# HTNB32L-XXX register map
File version: 0.9
CPU: CM3 r0p0, little endian, no MPU, no FPU, 3 interrupt priority bits
Registers are 32-bit, read-write, reset 0x0 unless marked. A register's access mark holds for its fields unless they carry their own. Offsets are from the block's base; [hi:lo] are bit positions; {n}, {i} and the like mark numbered series; 'fields as' and 'values as' point back to an identical list.

## IOCON (part 3 of 3) — IOCON pin configuration
Base 0x4002C000
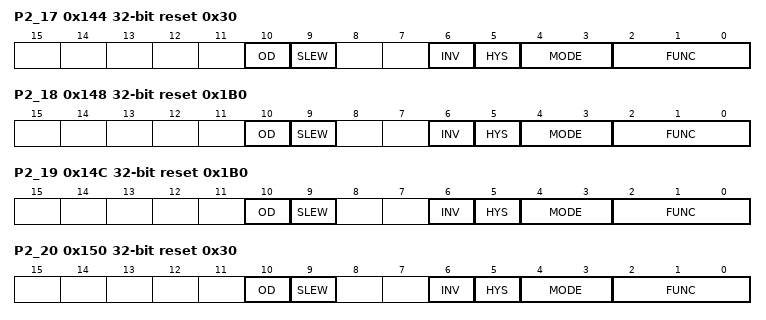
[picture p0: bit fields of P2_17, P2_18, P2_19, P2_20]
0x144 P2_17 reset 0x30 — I/O configuration register for pin P2[17]
  [10] OD — Open-drain mode.
    0=DISABLE; 1=ENABLED (Open-drain mode enabled. This is not a true open-drain mode. Input cannot be pulled up above VDD.)
  [9] SLEW — Driver slew rate
    0=STANDARD (Standard mode, output slew rate control is enabled. More outputs can be switched simultaneously.); 1=FAST (Fast mode, slew rate control is disabled. Refer to the appropriate specific device data sheet for details.)
  [6] INV — Invert input
    0=INPUT_NOT_INVERTED (Input not inverted (HIGH on pin reads as 1, LOW on pin reads as 0).); 1=INPUT_INVERTED_HIGH (Input inverted (HIGH on pin reads as 0, LOW on pin reads as 1).)
  [5] HYS — Hysteresis.
    0=DISABLE; 1=ENABLE
  [4:3] MODE — Selects function mode (on-chip pull-up/pull-down resistor control).
    0=INACTIVE (Inactive (no pull-down/pull-up resistor enabled).); 1=PULLDOWN_EN (Pull-down resistor enabled.); 2=PULLUP_EN (Pull-up resistor enabled.); 3=REPEATER_MODE
  [2:0] FUNC — Selects pin function for pin P2[17]
    0=P2_17 (General purpose digital input/output pin.); 1=EMC_RAS (LOW active SDRAM Row Address Strobe.)
0x148 P2_18 reset 0x1B0 — I/O configuration register for pin P2[18]
  [10] OD — Open-drain mode.
    values as P2_17.OD
  [9] SLEW — Driver slew rate
    values as P2_17.SLEW
  [6] INV — Invert input
    values as P2_17.INV
  [5] HYS — Hysteresis.
    0=DISABLE; 1=ENABLE
  [4:3] MODE — Selects function mode (on-chip pull-up/pull-down resistor control).
    values as P2_17.MODE
  [2:0] FUNC — Selects pin function for pin P2[18]
    0=P2_18 (General purpose digital input/output pin.); 1=EMC_CLK_0 (SDRAM clock 0.)
0x14C P2_19 reset 0x1B0 — I/O configuration register for pin P2[19]
  [10] OD — Open-drain mode.
    values as P2_17.OD
  [9] SLEW — Driver slew rate
    values as P2_17.SLEW
  [6] INV — Invert input
    values as P2_17.INV
  [5] HYS — Hysteresis.
    0=DISABLE; 1=ENABLE
  [4:3] MODE — Selects function mode (on-chip pull-up/pull-down resistor control).
    values as P2_17.MODE
  [2:0] FUNC — Selects pin function for pin P2[19]
    0=P2_19 (General purpose digital input/output pin.); 1=EMC_CLK_1 (SDRAM clock 1.)
0x150 P2_20 reset 0x30 — I/O configuration register for pin P2[20]
  [10] OD — Open-drain mode.
    values as P2_17.OD
  [9] SLEW — Driver slew rate
    values as P2_17.SLEW
  [6] INV — Invert input
    values as P2_17.INV
  [5] HYS — Hysteresis.
    0=DISABLE; 1=ENABLE
  [4:3] MODE — Selects function mode (on-chip pull-up/pull-down resistor control).
    values as P2_17.MODE
  [2:0] FUNC — Selects pin function for pin P2[20]
    0=P2_20 (General purpose digital input/output pin.); 1=EMC_DYCS0 (SDRAM chip select 0.)
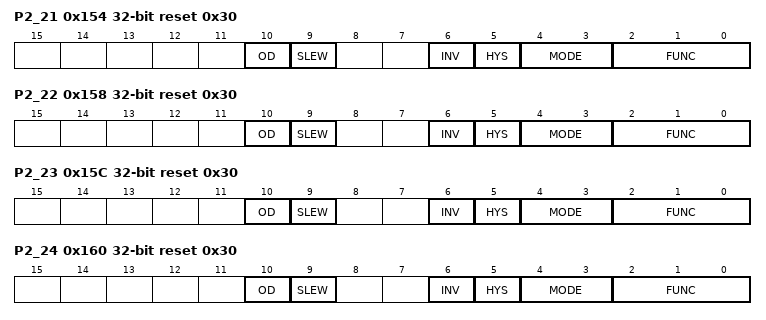
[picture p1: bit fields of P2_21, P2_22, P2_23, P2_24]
0x154 P2_21 reset 0x30 — I/O configuration register for pin P2[21]
  [10] OD — Open-drain mode.
    values as P2_17.OD
  [9] SLEW — Driver slew rate
    values as P2_17.SLEW
  [6] INV — Invert input
    values as P2_17.INV
  [5] HYS — Hysteresis.
    0=DISABLE; 1=ENABLE
  [4:3] MODE — Selects function mode (on-chip pull-up/pull-down resistor control).
    values as P2_17.MODE
  [2:0] FUNC — Selects pin function for pin P2[21]
    0=P2_21 (General purpose digital input/output pin.); 1=EMC_DYCS1 (SDRAM chip select 1.)
0x158 P2_22 reset 0x30 — I/O configuration register for pin P2[22]
  [10] OD — Open-drain mode.
    values as P2_17.OD
  [9] SLEW — Driver slew rate
    values as P2_17.SLEW
  [6] INV — Invert input
    values as P2_17.INV
  [5] HYS — Hysteresis.
    0=DISABLE; 1=ENABLE
  [4:3] MODE — Selects function mode (on-chip pull-up/pull-down resistor control).
    values as P2_17.MODE
  [2:0] FUNC — Selects pin function for pin P2[22]
    0=P2_22 (General purpose digital input/output pin.); 1=EMC_DYCS2 (SDRAM chip select 2.); 2=SSP0_SCK (Serial clock for SSP0.); 3=T3_CAP0 (Capture input for Timer 3, channel 0.)
0x15C P2_23 reset 0x30 — I/O configuration register for pin P2[23]
  [10] OD — Open-drain mode.
    values as P2_17.OD
  [9] SLEW — Driver slew rate
    values as P2_17.SLEW
  [6] INV — Invert input
    values as P2_17.INV
  [5] HYS — Hysteresis.
    0=DISABLE; 1=ENABLE
  [4:3] MODE — Selects function mode (on-chip pull-up/pull-down resistor control).
    values as P2_17.MODE
  [2:0] FUNC — Selects pin function for pin P2[23]
    0=P2_23 (General purpose digital input/output pin.); 1=EMC_DYCS3 (SDRAM chip select 3.); 2=SSP0_SSEL (Slave Select for SSP0.); 3=T3_CAP1 (Capture input for Timer 3, channel 1.)
0x160 P2_24 reset 0x30 — I/O configuration register for pin P2[24]
  [10] OD — Open-drain mode.
    values as P2_17.OD
  [9] SLEW — Driver slew rate
    values as P2_17.SLEW
  [6] INV — Invert input
    values as P2_17.INV
  [5] HYS — Hysteresis.
    0=DISABLE; 1=ENABLE
  [4:3] MODE — Selects function mode (on-chip pull-up/pull-down resistor control).
    values as P2_17.MODE
  [2:0] FUNC — Selects pin function for pin P2[24]
    0=P2_24 (General purpose digital input/output pin.); 1=EMC_CKE0 (SDRAM clock enable 0.)
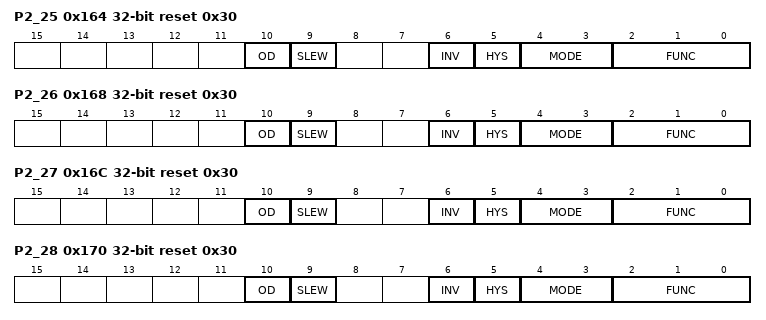
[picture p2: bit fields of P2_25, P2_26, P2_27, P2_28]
0x164 P2_25 reset 0x30 — I/O configuration register for pin P2[25]
  [10] OD — Open-drain mode.
    values as P2_17.OD
  [9] SLEW — Driver slew rate
    values as P2_17.SLEW
  [6] INV — Invert input
    values as P2_17.INV
  [5] HYS — Hysteresis.
    0=DISABLE; 1=ENABLE
  [4:3] MODE — Selects function mode (on-chip pull-up/pull-down resistor control).
    values as P2_17.MODE
  [2:0] FUNC — Selects pin function for pin P2[25]
    0=P2_25 (General purpose digital input/output pin.); 1=EMC_CKE1 (SDRAM clock enable 1.)
0x168 P2_26 reset 0x30 — I/O configuration register for pin P2[26]
  [10] OD — Open-drain mode.
    values as P2_17.OD
  [9] SLEW — Driver slew rate
    values as P2_17.SLEW
  [6] INV — Invert input
    values as P2_17.INV
  [5] HYS — Hysteresis.
    0=DISABLE; 1=ENABLE
  [4:3] MODE — Selects function mode (on-chip pull-up/pull-down resistor control).
    values as P2_17.MODE
  [2:0] FUNC — Selects pin function for pin P2[26]
    0=P2_26 (General purpose digital input/output pin.); 1=EMC_CKE2 (SDRAM clock enable 2.); 2=SSP0_MISO (Master In Slave Out for SSP0.); 3=T3_MAT0 (Match output for Timer 3, channel 0.)
0x16C P2_27 reset 0x30 — I/O configuration register for pin P2[27]
  [10] OD — Open-drain mode.
    values as P2_17.OD
  [9] SLEW — Driver slew rate
    values as P2_17.SLEW
  [6] INV — Invert input
    values as P2_17.INV
  [5] HYS — Hysteresis.
    0=DISABLE; 1=ENABLE
  [4:3] MODE — Selects function mode (on-chip pull-up/pull-down resistor control).
    values as P2_17.MODE
  [2:0] FUNC — Selects pin function for pin P2[27]
    0=P2_27 (General purpose digital input/output pin.); 1=EMC_CKE3 (SDRAM clock enable 3.); 2=SSP0_MOSI (Master Out Slave In for SSP0.); 3=T3_MAT1 (Match output for Timer 3, channel 1.)
0x170 P2_28 reset 0x30 — I/O configuration register for pin P2[28]
  [10] OD — Open-drain mode.
    values as P2_17.OD
  [9] SLEW — Driver slew rate
    values as P2_17.SLEW
  [6] INV — Invert input
    values as P2_17.INV
  [5] HYS — Hysteresis.
    0=DISABLE; 1=ENABLE
  [4:3] MODE — Selects function mode (on-chip pull-up/pull-down resistor control).
    values as P2_17.MODE
  [2:0] FUNC — Selects pin function for pin P2[28]
    0=P2_28 (General purpose digital input/output pin.); 1=EMC_DQM0 (Data mask 0 used with SDRAM and static devices.)
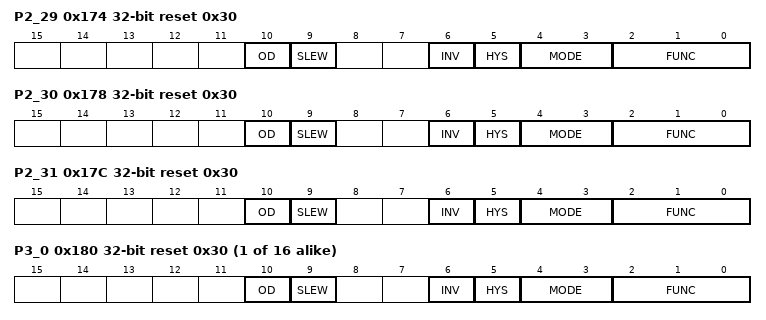
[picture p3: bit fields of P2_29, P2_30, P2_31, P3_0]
0x174 P2_29 reset 0x30 — I/O configuration register for pin P2[29]
  [10] OD — Open-drain mode.
    values as P2_17.OD
  [9] SLEW — Driver slew rate
    values as P2_17.SLEW
  [6] INV — Invert input
    values as P2_17.INV
  [5] HYS — Hysteresis.
    0=DISABLE; 1=ENABLE
  [4:3] MODE — Selects function mode (on-chip pull-up/pull-down resistor control).
    values as P2_17.MODE
  [2:0] FUNC — Selects pin function for pin P2[29]
    0=P2_29 (General purpose digital input/output pin.); 1=EMC_DQM1 (Data mask 1 used with SDRAM and static devices.)
0x178 P2_30 reset 0x30 — I/O configuration register for pin P2[30]
  [10] OD — Open-drain mode.
    values as P2_17.OD
  [9] SLEW — Driver slew rate
    values as P2_17.SLEW
  [6] INV — Invert input
    values as P2_17.INV
  [5] HYS — Hysteresis.
    0=DISABLE; 1=ENABLE
  [4:3] MODE — Selects function mode (on-chip pull-up/pull-down resistor control).
    values as P2_17.MODE
  [2:0] FUNC — Selects pin function for pin P2[30]
    0=P2_30 (General purpose digital input/output pin.); 1=EMC_DQM2 (Data mask 2 used with SDRAM and static devices.); 2=I2C2_SDA (I2C2 data input/output (this pin does not use a specialized I2C pad).); 3=T3_MAT2 (Match output for Timer 3, channel 2.)
0x17C P2_31 reset 0x30 — I/O configuration register for pin P2[31]
  [10] OD — Open-drain mode.
    values as P2_17.OD
  [9] SLEW — Driver slew rate
    values as P2_17.SLEW
  [6] INV — Invert input
    values as P2_17.INV
  [5] HYS — Hysteresis.
    0=DISABLE; 1=ENABLE
  [4:3] MODE — Selects function mode (on-chip pull-up/pull-down resistor control).
    values as P2_17.MODE
  [2:0] FUNC — Selects pin function for pin P2[31]
    0=P2_31 (General purpose digital input/output pin.); 1=EMC_DQM3 (Data mask 3 used with SDRAM and static devices.); 2=I2C2_SCL (I2C2 clock input/output (this pin does not use a specialized I2C pad).); 3=T3_MAT3 (Match output for Timer 3, channel 3.)
{0x180+4i} P3_{i} reset 0x30 (i=0..15) — I/O configuration register for pin P3[{i}]
  [10] OD — Open-drain mode.
    values as P2_17.OD
  [9] SLEW — Driver slew rate
    values as P2_17.SLEW
  [6] INV — Invert input
    values as P2_17.INV
  [5] HYS — Hysteresis.
    0=DISABLE; 1=ENABLE
  [4:3] MODE — Selects function mode (on-chip pull-up/pull-down resistor control).
    values as P2_17.MODE
  [2:0] FUNC — Selects pin function for pin P3[{i}]
    0=P3_{i} (General purpose digital input/output pin.); 1=EMC_D_{i} (External memory data line {i}.)
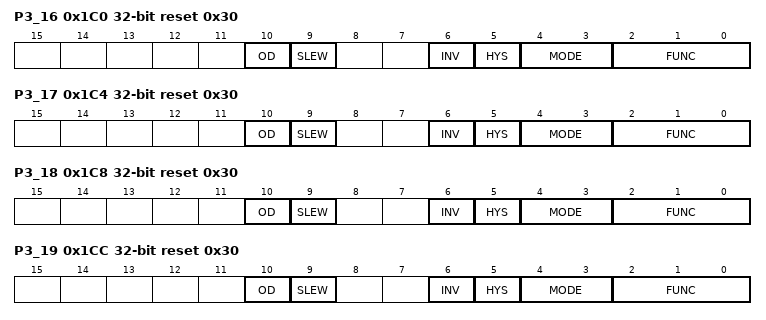
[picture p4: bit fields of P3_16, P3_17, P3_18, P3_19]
0x1C0 P3_16 reset 0x30 — I/O configuration register for pin P3[16]
  [10] OD — Open-drain mode.
    values as P2_17.OD
  [9] SLEW — Driver slew rate
    values as P2_17.SLEW
  [6] INV — Invert input
    values as P2_17.INV
  [5] HYS — Hysteresis.
    0=DISABLE; 1=ENABLE
  [4:3] MODE — Selects function mode (on-chip pull-up/pull-down resistor control).
    values as P2_17.MODE
  [2:0] FUNC — Selects pin function for pin P3[16]
    0=P3_16 (General purpose digital input/output pin.); 1=EMC_D_16 (External memory data line 16.); 2=PWM0_1 (Pulse Width Modulator 0, output 1.); 3=U1_TXD (Transmitter output for UART1.)
0x1C4 P3_17 reset 0x30 — I/O configuration register for pin P3[17]
  [10] OD — Open-drain mode.
    values as P2_17.OD
  [9] SLEW — Driver slew rate
    values as P2_17.SLEW
  [6] INV — Invert input
    values as P2_17.INV
  [5] HYS — Hysteresis.
    0=DISABLE; 1=ENABLE
  [4:3] MODE — Selects function mode (on-chip pull-up/pull-down resistor control).
    values as P2_17.MODE
  [2:0] FUNC — Selects pin function for pin P3[17]
    0=P3_17 (General purpose digital input/output pin.); 1=EMC_D_17 (External memory data line 17.); 2=PWM0_2 (Pulse Width Modulator 0, output 2.); 3=U1_RXD (Receiver input for UART1.)
0x1C8 P3_18 reset 0x30 — I/O configuration register for pin P3[18]
  [10] OD — Open-drain mode.
    values as P2_17.OD
  [9] SLEW — Driver slew rate
    values as P2_17.SLEW
  [6] INV — Invert input
    values as P2_17.INV
  [5] HYS — Hysteresis.
    0=DISABLE; 1=ENABLE
  [4:3] MODE — Selects function mode (on-chip pull-up/pull-down resistor control).
    values as P2_17.MODE
  [2:0] FUNC — Selects pin function for pin P3[18]
    0=P3_18 (General purpose digital input/output pin.); 1=EMC_D_18 (External memory data line 18.); 2=PWM0_3 (Pulse Width Modulator 0, output 3.); 3=U1_CTS (Clear to Send input for UART1.)
0x1CC P3_19 reset 0x30 — I/O configuration register for pin P3[19]
  [10] OD — Open-drain mode.
    values as P2_17.OD
  [9] SLEW — Driver slew rate
    values as P2_17.SLEW
  [6] INV — Invert input
    values as P2_17.INV
  [5] HYS — Hysteresis.
    0=DISABLE; 1=ENABLE
  [4:3] MODE — Selects function mode (on-chip pull-up/pull-down resistor control).
    values as P2_17.MODE
  [2:0] FUNC — Selects pin function for pin P3[19]
    0=P3_19 (General purpose digital input/output pin.); 1=EMC_D_19 (External memory data line 19.); 2=PWM0_4 (Pulse Width Modulator 0, output 4.); 3=U1_DCD (Data Carrier Detect input for UART1.)
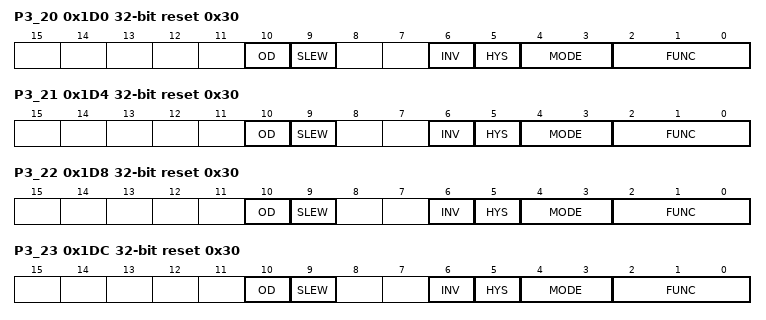
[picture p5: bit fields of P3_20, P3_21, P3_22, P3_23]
0x1D0 P3_20 reset 0x30 — I/O configuration register for pin P3[20]
  [10] OD — Open-drain mode.
    values as P2_17.OD
  [9] SLEW — Driver slew rate
    values as P2_17.SLEW
  [6] INV — Invert input
    values as P2_17.INV
  [5] HYS — Hysteresis.
    0=DISABLE; 1=ENABLE
  [4:3] MODE — Selects function mode (on-chip pull-up/pull-down resistor control).
    values as P2_17.MODE
  [2:0] FUNC — Selects pin function for pin P3[20]
    0=P3_20 (General purpose digital input/output pin.); 1=EMC_D_20 (External memory data line 20.); 2=PWM0_5 (Pulse Width Modulator 0, output 5.); 3=U1_DSR (Data Set Ready input for UART1.)
0x1D4 P3_21 reset 0x30 — I/O configuration register for pin P3[21]
  [10] OD — Open-drain mode.
    values as P2_17.OD
  [9] SLEW — Driver slew rate
    values as P2_17.SLEW
  [6] INV — Invert input
    values as P2_17.INV
  [5] HYS — Hysteresis.
    0=DISABLE; 1=ENABLE
  [4:3] MODE — Selects function mode (on-chip pull-up/pull-down resistor control).
    values as P2_17.MODE
  [2:0] FUNC — Selects pin function for pin P3[21]
    0=P3_21 (General purpose digital input/output pin.); 1=EMC_D_21 (External memory data line 21.); 2=PWM0_6 (Pulse Width Modulator 0, output 6.); 3=U1_DTR (Data Terminal Ready output for UART1. Can also be configured to be an RS-485/EIA-485 output enable signal for UART1.)
0x1D8 P3_22 reset 0x30 — I/O configuration register for pin P3[22]
  [10] OD — Open-drain mode.
    values as P2_17.OD
  [9] SLEW — Driver slew rate
    values as P2_17.SLEW
  [6] INV — Invert input
    values as P2_17.INV
  [5] HYS — Hysteresis.
    0=DISABLE; 1=ENABLE
  [4:3] MODE — Selects function mode (on-chip pull-up/pull-down resistor control).
    values as P2_17.MODE
  [2:0] FUNC — Selects pin function for pin P3[22]
    0=P3_22 (General purpose digital input/output pin.); 1=EMC_D_22 (External memory data line 22.); 2=PWM0_CAP0 (Capture input for PWM0, channel 0.); 3=U1_RI (Ring Indicator input for UART1.)
0x1DC P3_23 reset 0x30 — I/O configuration register for pin P3[23]
  [10] OD — Open-drain mode.
    values as P2_17.OD
  [9] SLEW — Driver slew rate
    values as P2_17.SLEW
  [6] INV — Invert input
    values as P2_17.INV
  [5] HYS — Hysteresis.
    0=DISABLE; 1=ENABLE
  [4:3] MODE — Selects function mode (on-chip pull-up/pull-down resistor control).
    values as P2_17.MODE
  [2:0] FUNC — Selects pin function for pin P3[23]
    0=P3_23 (General purpose digital input/output pin.); 1=EMC_D_23 (External memory data line 23.); 2=PWM1_CAP0 (Capture input for PWM1, channel 0.); 3=T0_CAP0 (Capture input for Timer 0, channel 0.)
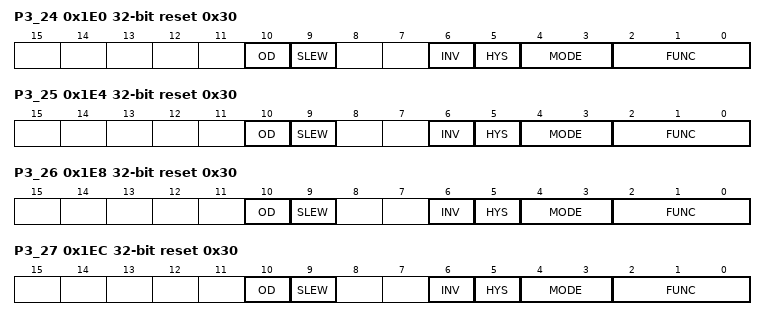
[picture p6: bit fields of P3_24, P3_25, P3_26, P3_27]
0x1E0 P3_24 reset 0x30 — I/O configuration register for pin P3[24]
  [10] OD — Open-drain mode.
    values as P2_17.OD
  [9] SLEW — Driver slew rate
    values as P2_17.SLEW
  [6] INV — Invert input
    values as P2_17.INV
  [5] HYS — Hysteresis.
    0=DISABLE; 1=ENABLE
  [4:3] MODE — Selects function mode (on-chip pull-up/pull-down resistor control).
    values as P2_17.MODE
  [2:0] FUNC — Selects pin function for pin P3[24]
    0=P3_24 (General purpose digital input/output pin.); 1=EMC_D_24 (External memory data line 24.); 2=PWM1_1 (Pulse Width Modulator 1, output 1.); 3=T0_CAP1 (Capture input for Timer 0, channel 1.)
0x1E4 P3_25 reset 0x30 — I/O configuration register for pin P3[25]
  [10] OD — Open-drain mode.
    values as P2_17.OD
  [9] SLEW — Driver slew rate
    values as P2_17.SLEW
  [6] INV — Invert input
    values as P2_17.INV
  [5] HYS — Hysteresis.
    0=DISABLE; 1=ENABLE
  [4:3] MODE — Selects function mode (on-chip pull-up/pull-down resistor control).
    values as P2_17.MODE
  [2:0] FUNC — Selects pin function for pin P3[25]
    0=P3_25 (General purpose digital input/output pin.); 1=EMC_D_25 (External memory data line 25.); 2=PWM1_2 (Pulse Width Modulator 1, output 2.); 3=T0_MAT0 (Match output for Timer 0, channel 0.)
0x1E8 P3_26 reset 0x30 — I/O configuration register for pin P3[26]
  [10] OD — Open-drain mode.
    values as P2_17.OD
  [9] SLEW — Driver slew rate
    values as P2_17.SLEW
  [6] INV — Invert input
    values as P2_17.INV
  [5] HYS — Hysteresis.
    0=DISABLE; 1=ENABLE
  [4:3] MODE — Selects function mode (on-chip pull-up/pull-down resistor control).
    values as P2_17.MODE
  [2:0] FUNC — Selects pin function for pin P3[26]
    0=P3_26 (General purpose digital input/output pin.); 1=EMC_D_26 (External memory data line 26.); 2=PWM1_3 (Pulse Width Modulator 1, output 3.); 3=T0_MAT1 (Match output for Timer 0, channel 1.); 4=STCLK (System tick timer clock input.)
0x1EC P3_27 reset 0x30 — I/O configuration register for pin P3[27]
  [10] OD — Open-drain mode.
    values as P2_17.OD
  [9] SLEW — Driver slew rate
    values as P2_17.SLEW
  [6] INV — Invert input
    values as P2_17.INV
  [5] HYS — Hysteresis.
    0=DISABLE; 1=ENABLE
  [4:3] MODE — Selects function mode (on-chip pull-up/pull-down resistor control).
    values as P2_17.MODE
  [2:0] FUNC — Selects pin function for pin P3[27]
    0=P3_27 (General purpose digital input/output pin.); 1=EMC_D_27 (External memory data line 27.); 2=PWM1_4 (Pulse Width Modulator 1, output 4.); 3=T1_CAP0 (Capture input for Timer 1, channel 0.)
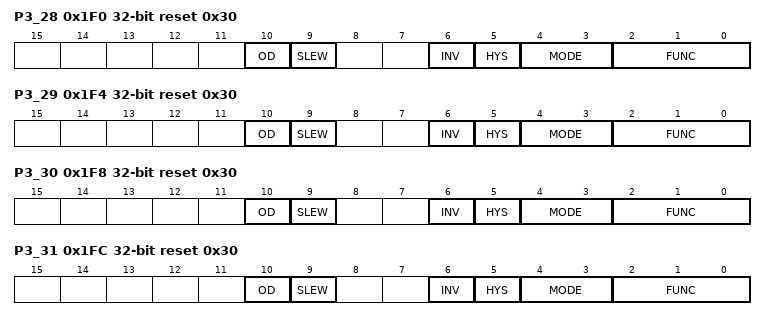
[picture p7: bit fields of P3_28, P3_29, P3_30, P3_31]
0x1F0 P3_28 reset 0x30 — I/O configuration register for pin P3[28]
  [10] OD — Open-drain mode.
    values as P2_17.OD
  [9] SLEW — Driver slew rate
    values as P2_17.SLEW
  [6] INV — Invert input
    values as P2_17.INV
  [5] HYS — Hysteresis.
    0=DISABLE; 1=ENABLE
  [4:3] MODE — Selects function mode (on-chip pull-up/pull-down resistor control).
    values as P2_17.MODE
  [2:0] FUNC — Selects pin function for pin P3[28]
    0=P3_28 (General purpose digital input/output pin.); 1=EMC_D_28 (External memory data line 28.); 2=PWM1_5 (Pulse Width Modulator 1, output 5.); 3=T1_CAP1 (Capture input for Timer 1, channel 1.)
0x1F4 P3_29 reset 0x30 — I/O configuration register for pin P3[29]
  [10] OD — Open-drain mode.
    values as P2_17.OD
  [9] SLEW — Driver slew rate
    values as P2_17.SLEW
  [6] INV — Invert input
    values as P2_17.INV
  [5] HYS — Hysteresis.
    0=DISABLE; 1=ENABLE
  [4:3] MODE — Selects function mode (on-chip pull-up/pull-down resistor control).
    values as P2_17.MODE
  [2:0] FUNC — Selects pin function for pin P3[29]
    0=P3_29 (General purpose digital input/output pin.); 1=EMC_D_29 (External memory data line 29.); 2=PWM1_6 (Pulse Width Modulator 1, output 6.); 3=T1_MAT0 (Match output for Timer 1, channel 0.)
0x1F8 P3_30 reset 0x30 — I/O configuration register for pin P3[30]
  [10] OD — Open-drain mode.
    values as P2_17.OD
  [9] SLEW — Driver slew rate
    values as P2_17.SLEW
  [6] INV — Invert input
    values as P2_17.INV
  [5] HYS — Hysteresis.
    0=DISABLE; 1=ENABLE
  [4:3] MODE — Selects function mode (on-chip pull-up/pull-down resistor control).
    values as P2_17.MODE
  [2:0] FUNC — Selects pin function for pin P3[30]
    0=P3_30 (General purpose digital input/output pin.); 1=EMC_D_30 (External memory data line 30.); 2=U1_RTS (Request to Send output for UART1. Can also be configured to be an RS-485/EIA-485 output enable signal for UART1.); 3=T1_MAT1 (Match output for Timer 1, channel 1.)
0x1FC P3_31 reset 0x30 — I/O configuration register for pin P3[31]
  [10] OD — Open-drain mode.
    values as P2_17.OD
  [9] SLEW — Driver slew rate
    values as P2_17.SLEW
  [6] INV — Invert input
    values as P2_17.INV
  [5] HYS — Hysteresis.
    0=DISABLE; 1=ENABLE
  [4:3] MODE — Selects function mode (on-chip pull-up/pull-down resistor control).
    values as P2_17.MODE
  [2:0] FUNC — Selects pin function for pin P3[31]
    0=P3_31 (General purpose digital input/output pin.); 1=EMC_D_31 (External memory data line 31.); 3=T1_MAT2 (Match output for Timer 1, channel 2.)
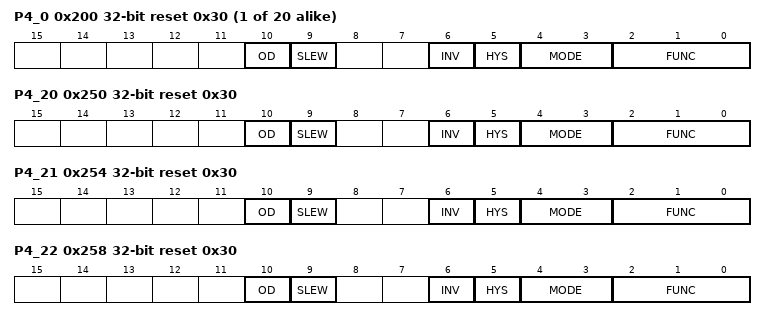
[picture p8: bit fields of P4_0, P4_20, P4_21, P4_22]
{0x200+4i} P4_{i} reset 0x30 (i=0..19) — I/O configuration register for pin P4[{i}]
  [10] OD — Open-drain mode.
    values as P2_17.OD
  [9] SLEW — Driver slew rate
    values as P2_17.SLEW
  [6] INV — Invert input
    values as P2_17.INV
  [5] HYS — Hysteresis.
    0=DISABLE; 1=ENABLE
  [4:3] MODE — Selects function mode (on-chip pull-up/pull-down resistor control).
    values as P2_17.MODE
  [2:0] FUNC — Selects pin function for pin P4[{i}]
    0=P4_{i} (General purpose digital input/output pin.); 1=EMC_A_{i} (External memory address line {i}.)
0x250 P4_20 reset 0x30 — I/O configuration register for pin P4[20]
  [10] OD — Open-drain mode.
    values as P2_17.OD
  [9] SLEW — Driver slew rate
    values as P2_17.SLEW
  [6] INV — Invert input
    values as P2_17.INV
  [5] HYS — Hysteresis.
    0=DISABLE; 1=ENABLE
  [4:3] MODE — Selects function mode (on-chip pull-up/pull-down resistor control).
    values as P2_17.MODE
  [2:0] FUNC — Selects pin function for pin P4[20]
    0=P4_20 (General purpose digital input/output pin.); 1=EMC_A_20 (External memory address line 20.); 2=I2C2_SDA (I2C2 data input/output (this pin does not use a specialized I2C pad).); 3=SSP1_SCK (Serial Clock for SSP1.)
0x254 P4_21 reset 0x30 — I/O configuration register for pin P4[21]
  [10] OD — Open-drain mode.
    values as P2_17.OD
  [9] SLEW — Driver slew rate
    values as P2_17.SLEW
  [6] INV — Invert input
    values as P2_17.INV
  [5] HYS — Hysteresis.
    0=DISABLE; 1=ENABLE
  [4:3] MODE — Selects function mode (on-chip pull-up/pull-down resistor control).
    values as P2_17.MODE
  [2:0] FUNC — Selects pin function for pin P4[21]
    0=P4_21 (General purpose digital input/output pin.); 1=EMC_A_21 (External memory address line 21.); 2=I2C2_SCL (I2C2 clock input/output (this pin does not use a specialized I2C pad).); 3=SSP1_SSEL (Slave Select for SSP1.)
0x258 P4_22 reset 0x30 — I/O configuration register for pin P4[22]
  [10] OD — Open-drain mode.
    values as P2_17.OD
  [9] SLEW — Driver slew rate
    values as P2_17.SLEW
  [6] INV — Invert input
    values as P2_17.INV
  [5] HYS — Hysteresis.
    0=DISABLE; 1=ENABLE
  [4:3] MODE — Selects function mode (on-chip pull-up/pull-down resistor control).
    values as P2_17.MODE
  [2:0] FUNC — Selects pin function for pin P4[22]
    0=P4_22 (General purpose digital input/output pin.); 1=EMC_A_22 (External memory address line 22.); 2=U2_TXD (Transmitter output for UART2.); 3=SSP1_MISO (Master In Slave Out for SSP1.)
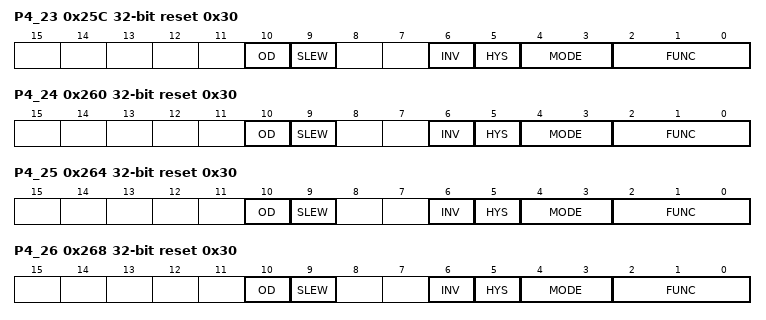
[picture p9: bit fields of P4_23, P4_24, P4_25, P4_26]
0x25C P4_23 reset 0x30 — I/O configuration register for pin P4[23]
  [10] OD — Open-drain mode.
    values as P2_17.OD
  [9] SLEW — Driver slew rate
    values as P2_17.SLEW
  [6] INV — Invert input
    values as P2_17.INV
  [5] HYS — Hysteresis.
    0=DISABLE; 1=ENABLE
  [4:3] MODE — Selects function mode (on-chip pull-up/pull-down resistor control).
    values as P2_17.MODE
  [2:0] FUNC — Selects pin function for pin P4[23]
    0=P4_23 (General purpose digital input/output pin.); 1=EMC_A_23 (External memory address line 23.); 2=U2_RXD (Receiver input for UART2.); 3=SSP1_MOSI (Master Out Slave In for SSP1.)
0x260 P4_24 reset 0x30 — I/O configuration register for pin P4[24]
  [10] OD — Open-drain mode.
    values as P2_17.OD
  [9] SLEW — Driver slew rate
    values as P2_17.SLEW
  [6] INV — Invert input
    values as P2_17.INV
  [5] HYS — Hysteresis.
    0=DISABLE; 1=ENABLE
  [4:3] MODE — Selects function mode (on-chip pull-up/pull-down resistor control).
    values as P2_17.MODE
  [2:0] FUNC — Selects pin function for pin P4[24]
    0=P4_24 (General purpose digital input/output pin.); 1=EMC_OE (LOW active Output Enable signal.)
0x264 P4_25 reset 0x30 — I/O configuration register for pin P4[25]
  [10] OD — Open-drain mode.
    values as P2_17.OD
  [9] SLEW — Driver slew rate
    values as P2_17.SLEW
  [6] INV — Invert input
    values as P2_17.INV
  [5] HYS — Hysteresis.
    0=DISABLE; 1=ENABLE
  [4:3] MODE — Selects function mode (on-chip pull-up/pull-down resistor control).
    values as P2_17.MODE
  [2:0] FUNC — Selects pin function for pin P4[25]
    0=P4_25 (General purpose digital input/output pin.); 1=EMC_WE (LOW active Write Enable signal.)
0x268 P4_26 reset 0x30 — I/O configuration register for pin P4[26]
  [10] OD — Open-drain mode.
    values as P2_17.OD
  [9] SLEW — Driver slew rate
    values as P2_17.SLEW
  [6] INV — Invert input
    values as P2_17.INV
  [5] HYS — Hysteresis.
    0=DISABLE; 1=ENABLE
  [4:3] MODE — Selects function mode (on-chip pull-up/pull-down resistor control).
    values as P2_17.MODE
  [2:0] FUNC — Selects pin function for pin P4[26]
    0=P4_26 (General purpose digital input/output pin.); 1=EMC_BLS0 (LOW active Byte Lane select signal 0.)
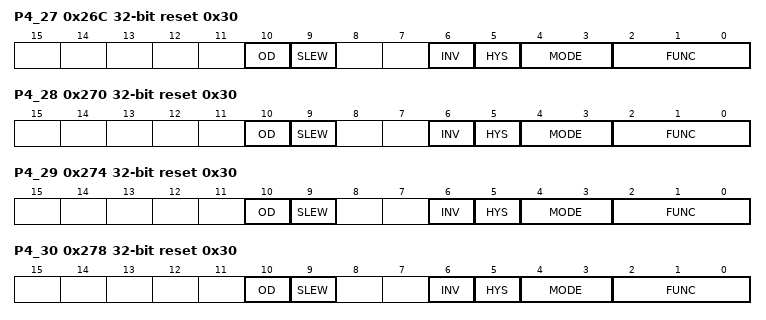
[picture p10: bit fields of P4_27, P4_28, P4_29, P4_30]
0x26C P4_27 reset 0x30 — I/O configuration register for pin P4[27]
  [10] OD — Open-drain mode.
    values as P2_17.OD
  [9] SLEW — Driver slew rate
    values as P2_17.SLEW
  [6] INV — Invert input
    values as P2_17.INV
  [5] HYS — Hysteresis.
    0=DISABLE; 1=ENABLE
  [4:3] MODE — Selects function mode (on-chip pull-up/pull-down resistor control).
    values as P2_17.MODE
  [2:0] FUNC — Selects pin function for pin P4[27]
    0=P4_27 (General purpose digital input/output pin.); 1=EMC_BLS1 (LOW active Byte Lane select signal 1.)
0x270 P4_28 reset 0x30 — I/O configuration register for pin P4[28]
  [10] OD — Open-drain mode.
    values as P2_17.OD
  [9] SLEW — Driver slew rate
    values as P2_17.SLEW
  [6] INV — Invert input
    values as P2_17.INV
  [5] HYS — Hysteresis.
    0=DISABLE; 1=ENABLE
  [4:3] MODE — Selects function mode (on-chip pull-up/pull-down resistor control).
    values as P2_17.MODE
  [2:0] FUNC — Selects pin function for pin P4[28]
    0=P4_28 (General purpose digital input/output pin.); 1=EMC_BLS2 (LOW active Byte Lane select signal 2.); 2=U3_TXD (Transmitter output for UART3.); 3=T2_MAT0 (Match output for Timer 2, channel 0.); 5=LCD_VD_6 (LCD data.); 6=LCD_VD_10 (LCD data.); 7=LCD_VD_2 (LCD data.)
0x274 P4_29 reset 0x30 — I/O configuration register for pin P4[29]
  [10] OD — Open-drain mode.
    values as P2_17.OD
  [9] SLEW — Driver slew rate
    values as P2_17.SLEW
  [6] INV — Invert input
    values as P2_17.INV
  [5] HYS — Hysteresis.
    0=DISABLE; 1=ENABLE
  [4:3] MODE — Selects function mode (on-chip pull-up/pull-down resistor control).
    values as P2_17.MODE
  [2:0] FUNC — Selects pin function for pin P4[29]
    0=P4_29 (General purpose digital input/output pin.); 1=EMC_BLS3 (LOW active Byte Lane select signal 3.); 2=U3_RXD (Receiver input for UART3.); 3=T2_MAT1 (Match output for Timer 2, channel 1.); 4=I2C2_SCL (I2C2 clock input/output (this pin does not use a specialized I2C pad).); 5=LCD_VD_7 (LCD data.); 6=LCD_VD_11 (LCD data.); 7=LCD_VD_3 (LCD data.)
0x278 P4_30 reset 0x30 — I/O configuration register for pin P4[30]
  [10] OD — Open-drain mode.
    values as P2_17.OD
  [9] SLEW — Driver slew rate
    values as P2_17.SLEW
  [6] INV — Invert input
    values as P2_17.INV
  [5] HYS — Hysteresis.
    0=DISABLE; 1=ENABLE
  [4:3] MODE — Selects function mode (on-chip pull-up/pull-down resistor control).
    values as P2_17.MODE
  [2:0] FUNC — Selects pin function for pin P4[30]
    0=P4_30 (General purpose digital input/output pin.); 1=EMC_CS0 (LOW active Chip Select 0 signal.)
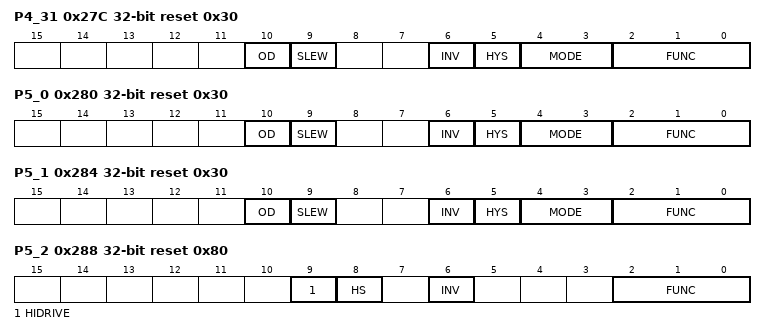
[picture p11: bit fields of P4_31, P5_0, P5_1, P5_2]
0x27C P4_31 reset 0x30 — I/O configuration register for pin P4[31]
  [10] OD — Open-drain mode.
    values as P2_17.OD
  [9] SLEW — Driver slew rate
    values as P2_17.SLEW
  [6] INV — Invert input
    values as P2_17.INV
  [5] HYS — Hysteresis.
    0=DISABLE; 1=ENABLE
  [4:3] MODE — Selects function mode (on-chip pull-up/pull-down resistor control).
    values as P2_17.MODE
  [2:0] FUNC — Selects pin function for pin P4[31]
    0=P4_31 (General purpose digital input/output pin.); 1=EMC_CS1 (LOW active Chip Select 1 signal.)
0x280 P5_0 reset 0x30 — I/O configuration register for pin P5[0]
  [10] OD — Open-drain mode.
    values as P2_17.OD
  [9] SLEW — Driver slew rate
    values as P2_17.SLEW
  [6] INV — Invert input
    values as P2_17.INV
  [5] HYS — Hysteresis.
    0=DISABLE; 1=ENABLE
  [4:3] MODE — Selects function mode (on-chip pull-up/pull-down resistor control).
    values as P2_17.MODE
  [2:0] FUNC — Selects pin function for pin P5[0]
    0=P5_0 (General purpose digital input/output pin.); 1=EMC_A_24 (External memory address line 24.); 2=SSP2_MOSI (Master Out Slave In for SSP2.); 3=T2_MAT2 (Match output for Timer 2, channel 2.)
0x284 P5_1 reset 0x30 — I/O configuration register for pin P5[1]
  [10] OD — Open-drain mode.
    values as P2_17.OD
  [9] SLEW — Driver slew rate
    values as P2_17.SLEW
  [6] INV — Invert input
    values as P2_17.INV
  [5] HYS — Hysteresis.
    0=DISABLE; 1=ENABLE
  [4:3] MODE — Selects function mode (on-chip pull-up/pull-down resistor control).
    values as P2_17.MODE
  [2:0] FUNC — Selects pin function for pin P5[1]
    0=P5_1 (General purpose digital input/output pin.); 1=EMC_A_25 (External memory address line 25.); 2=SSP2_MISO (Master In Slave Out for SSP2.); 3=T2_MAT3 (Match output for Timer 2, channel 3.)
0x288 P5_2 reset 0x80 — I/O configuration register for pin P5[2]
  [9] HIDRIVE — Controls sink current capability of the pin, only for P5[2] and P5[3].
    0=LOWDRIVE (Output drive sink is 4 mA. This is sufficient for standard and fast mode I2C.); 1=HIGHDRIVE (Output drive sink is 20 mA. This is needed for Fast Mode Plus I2C. Refer to the appropriate specific device data sheet for details.)
  [8] HS — Configures I2C features for standard mode, fast mode, and Fast Mode Plus operation.
    0=ENABLED (I2C 50ns glitch filter and slew rate control enabled.); 1=DISABLED (I2C 50ns glitch filter and slew rate control disabled.)
  [6] INV — Invert input
    values as P2_17.INV
  [2:0] FUNC — Selects pin function for pin P5[2]
    0=P5_2 (General purpose digital input/output pin.); 3=T3_MAT2 (Match output for Timer 3, channel 2.); 5=I2C0_SDA (I2C0 data input/output (this pin uses a specialized I2C pad that supports I2C Fast Mode Plus).)
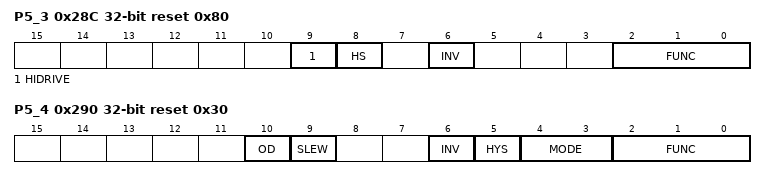
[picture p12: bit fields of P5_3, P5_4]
0x28C P5_3 reset 0x80 — I/O configuration register for pin P5[3]
  [9] HIDRIVE — Controls sink current capability of the pin, only for P5[2] and P5[3].
    values as P5_2.HIDRIVE
  [8] HS — Configures I2C features for standard mode, fast mode, and Fast Mode Plus operation.
    values as P5_2.HS
  [6] INV — Invert input
    values as P2_17.INV
  [2:0] FUNC — Selects pin function for pin P5[3]
    0=P5_3 (General purpose digital input/output pin.); 4=U4_RXD (Receiver input for USART4.); 5=I2C0_SCL (I2C0 clock input/output (this pin uses a specialized I2C pad that supports I2C Fast Mode Plus.)
0x290 P5_4 reset 0x30 — I/O configuration register for pin P5[4]
  [10] OD — Open-drain mode.
    values as P2_17.OD
  [9] SLEW — Driver slew rate
    values as P2_17.SLEW
  [6] INV — Invert input
    values as P2_17.INV
  [5] HYS — Hysteresis.
    0=DISABLE; 1=ENABLE
  [4:3] MODE — Selects function mode (on-chip pull-up/pull-down resistor control).
    values as P2_17.MODE
  [2:0] FUNC — Selects pin function for pin P5[4]
    0=P5_4 (General purpose digital input/output pin.); 1=U0_OE (RS-485/EIA-485 output enable signal for UART0.); 3=T3_MAT3 (Match output for Timer 3, channel 3.); 4=U4_TXD (Transmitter output for USART4 (input/output in smart card mode).)
